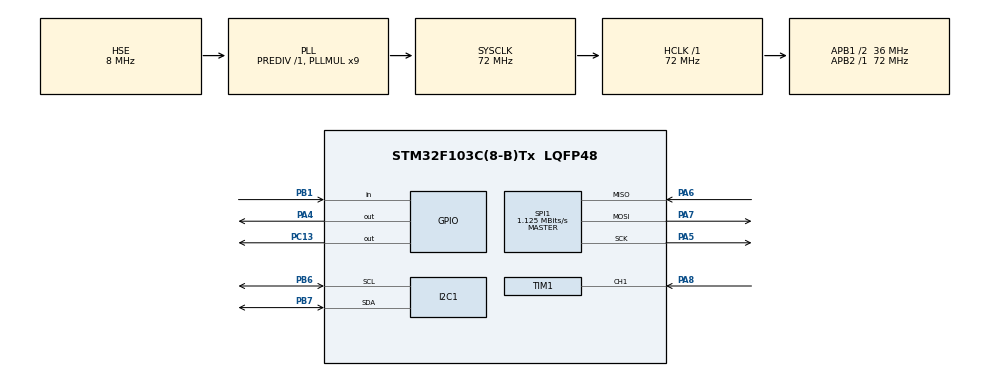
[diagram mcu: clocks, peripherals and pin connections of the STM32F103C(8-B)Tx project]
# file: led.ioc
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Mcu.Family=STM32F1
Mcu.Name=STM32F103C(8-B)Tx
Mcu.Package=LQFP48
NVIC.PriorityGroup=NVIC_PRIORITYGROUP_4
NVIC.TIM1_CC_IRQn=true\:0\:0\:false\:false\:true\:true\:true\:true
NVIC.TIM1_UP_IRQn=true\:0\:0\:false\:false\:true\:true\:true\:true
PA13.Mode=Serial_Wire
PA13.Signal=SYS_JTMS-SWDIO
PA14.Mode=Serial_Wire
PA14.Signal=SYS_JTCK-SWCLK
PA4.GPIO_Speed=GPIO_SPEED_FREQ_HIGH
PA4.PinState=GPIO_PIN_SET
PA4.Signal=GPIO_Output
PA5.Mode=Full_Duplex_Master
PA5.Signal=SPI1_SCK
PA6.Mode=Full_Duplex_Master
PA6.Signal=SPI1_MISO
PA7.Mode=Full_Duplex_Master
PA7.Signal=SPI1_MOSI
PA8.Signal=S_TIM1_CH1
PB1.GPIO_PuPd=GPIO_PULLUP
PB1.Signal=GPIO_Input
PB6.Mode=I2C
PB6.Signal=I2C1_SCL
PB7.Mode=I2C
PB7.Signal=I2C1_SDA
PC13-TAMPER-RTC.PinState=GPIO_PIN_SET
PC13-TAMPER-RTC.Signal=GPIO_Output
PC14-OSC32_IN.Mode=LSE-External-Oscillator
PC14-OSC32_IN.Signal=RCC_OSC32_IN
PC15-OSC32_OUT.Mode=LSE-External-Oscillator
PC15-OSC32_OUT.Signal=RCC_OSC32_OUT
PD0-OSC_IN.Mode=HSE-External-Oscillator
PD0-OSC_IN.Signal=RCC_OSC_IN
PD1-OSC_OUT.Mode=HSE-External-Oscillator
PD1-OSC_OUT.Signal=RCC_OSC_OUT
ProjectManager.HeapSize=0x200
ProjectManager.StackSize=0x400
ProjectManager.TargetToolchain=CMake
RCC.AHBFreq_Value=72000000
RCC.APB1CLKDivider=RCC_HCLK_DIV2
RCC.APB1Freq_Value=36000000
RCC.APB1TimFreq_Value=72000000
RCC.APB2Freq_Value=72000000
RCC.APB2TimFreq_Value=72000000
RCC.HCLKFreq_Value=72000000
RCC.PLLMUL=RCC_PLL_MUL9
RCC.PLLSourceVirtual=RCC_PLLSOURCE_HSE
RCC.SYSCLKFreq_VALUE=72000000
RCC.SYSCLKSource=RCC_SYSCLKSOURCE_PLLCLK
RCC.USBFreq_Value=72000000
SH.S_TIM1_CH1.0=TIM1_CH1,Input_Capture1_from_TI1
SPI1.BaudRatePrescaler=SPI_BAUDRATEPRESCALER_64
SPI1.CalculateBaudRate=1.125 MBits/s
SPI1.Direction=SPI_DIRECTION_2LINES
SPI1.Mode=SPI_MODE_MASTER
SPI1.VirtualType=VM_MASTER
TIM1.AutoReloadPreload=TIM_AUTORELOAD_PRELOAD_ENABLE
TIM1.Channel-Input_Capture1_from_TI1=TIM_CHANNEL_1
TIM1.Channel-Input_Capture2_from_TI1_63=TIM_CHANNEL_2
TIM1.ICPolarity_CH1=TIM_INPUTCHANNELPOLARITY_FALLING
TIM1.ICPolarity_CH2=TIM_INPUTCHANNELPOLARITY_RISING
TIM1.Period=65535
TIM1.Prescaler=71
VP_TIM1_VS_ClockSourceINT.Mode=Internal
VP_TIM1_VS_indirect_ch1.Mode=Input_Capture2_from_TI1_63
board=custom

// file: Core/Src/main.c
/* USER CODE BEGIN Header */
/**
  ******************************************************************************
  * @file           : main.c
  * @brief          : Main program body
  ******************************************************************************
  * @attention
  *
  * Copyright (c) 2025 STMicroelectronics.
  * All rights reserved.
  *
  * This software is licensed under terms that can be found in the LICENSE file
  * in the root directory of this software component.
  * If no LICENSE file comes with this software, it is provided AS-IS.
  *
  ******************************************************************************
  */
/* USER CODE END Header */
#include "main.h"
#include "i2c.h"
#include "spi.h"
#include "tim.h"
#include "gpio.h"

/* USER CODE BEGIN Includes */
#include "math.h"
#include "driver_keyboard.h"
#include "driver_W25Q64.h"
#include "driver_oled_hardware.h"
/* USER CODE END Includes */

void SystemClock_Config(void);

/* USER CODE BEGIN 0 */
// uint8_t led_status = 0;
// uint8_t addr[3] = {0x00, 0x00, 0x00};
// uint8_t write_buffer[] = {0x01, 0x02, 0x03, 0x04};
// uint8_t read_buffer[4] = {0xff, 0xff, 0xff, 0xff};
// uint8_t mid;
// uint16_t did;
/* USER CODE END 0 */

int main(void)
{

  /* MCU Configuration--------------------------------------------------------*/

  /* Reset of all peripherals, Initializes the Flash interface and the Systick. */
  HAL_Init();

  /* Configure the system clock */
  SystemClock_Config();

  /* Initialize all configured peripherals */
  MX_GPIO_Init();
  MX_SPI1_Init();
  MX_I2C1_Init();
  MX_TIM1_Init();
  /* USER CODE BEGIN 2 */
  // OLED_Init();

  // OLED_ShowString(1, 1, "MID:   DID:");
  // OLED_ShowString(2, 1, "W:");
  // OLED_ShowString(3, 1, "R:");

  // ReadID(&mid, &did);
  // OLED_ShowHexNum(1, 5, mid, 2);
  // OLED_ShowHexNum(1, 12, did, 4);

  // SectorErase(addr);
  // ReadData(addr, read_buffer, 4);
  // OLED_ShowHexNum(3, 3, read_buffer[0], 2);
  // OLED_ShowHexNum(3, 6, read_buffer[1], 2);
  // OLED_ShowHexNum(3, 9, read_buffer[2], 2);
  // OLED_ShowHexNum(3, 12, read_buffer[3], 2);

  // PageProgram(addr, write_buffer, 4);

  // ReadData(addr, read_buffer, 4);

  // OLED_ShowHexNum(2, 3, write_buffer[0], 2);
  // OLED_ShowHexNum(2, 6, write_buffer[1], 2);
  // OLED_ShowHexNum(2, 9, write_buffer[2], 2);
  // OLED_ShowHexNum(2, 13, write_buffer[3], 2);

  // OLED_ShowHexNum(3, 3, read_buffer[0], 2);
  // OLED_ShowHexNum(3, 6, read_buffer[1], 2);
  // OLED_ShowHexNum(3, 9, read_buffer[2], 2);
  // OLED_ShowHexNum(3, 12, read_buffer[3], 2);
  // ReadData(addr, &led_status, 1);
  // if (led_status == 0)
  // {
  //   HAL_GPIO_WritePin(GPIOC, GPIO_PIN_13, GPIO_PIN_SET);
  // }
  // else
  // {
  //   HAL_GPIO_WritePin(GPIOC, GPIO_PIN_13, GPIO_PIN_RESET);
  // }
  /* USER CODE END 2 */

  /* Infinite loop */
  /* USER CODE BEGIN WHILE */
  // HAL_TIM_PWM_Start(&htim1, TIM_CHANNEL_1);
  HAL_TIM_IC_Start_IT(&htim1, TIM_CHANNEL_1); // 启动通道 1 的输入捕获
  HAL_TIM_IC_Start_IT(&htim1, TIM_CHANNEL_2); // 启动通道 2 的输入捕获并启用中断
  while (1)
  {
    /* USER CODE END WHILE */

    /* USER CODE BEGIN 3 */
    // float t = HAL_GetTick() / 1000.0f;
    // float duty = 0.5 * sin(2 * 3.14 * t) + 0.5;
    // uint16_t ccr = duty * 1000;
    // __HAL_TIM_SET_COMPARE(&htim1, TIM_CHANNEL_1, ccr);

    // if(Keyboard_GetNum() == 1){
    //   SectorErase(addr);
    //   PageProgram(addr, write_buffer, 4);
    //   write_buffer[0]++;
    //   write_buffer[1]++;
    //   write_buffer[2]++;
    //   write_buffer[3]++;

    //   OLED_ShowHexNum(2, 1, write_buffer[0], 2);
    //   OLED_ShowHexNum(2, 3, write_buffer[1], 2);
    //   OLED_ShowHexNum(2, 5, write_buffer[2], 2);
    //   OLED_ShowHexNum(2, 7, write_buffer[3], 2);

    //   ReadData(addr, read_buffer, 4);
    //   OLED_ShowHexNum(3, 1, read_buffer[0], 2);
    //   OLED_ShowHexNum(3, 3, read_buffer[1], 2);
    //   OLED_ShowHexNum(3, 5, read_buffer[2], 2);
    //   OLED_ShowHexNum(3, 7, read_buffer[3], 2);
    // }
    // if(Keyboard_GetNum() == 1){
    //   HAL_GPIO_TogglePin(GPIOC, GPIO_PIN_13);
    //   if (HAL_GPIO_ReadPin(GPIOC, GPIO_PIN_13) == GPIO_PIN_SET)
    //   {
    //     led_status = 0;
    //   }else{
    //     led_status = 1;
    //   }
    //   SectorErase(addr);
    //   PageProgram(addr, &led_status, 1);
    // }
  }
  /* USER CODE END 3 */
}

void SystemClock_Config(void)
{
  RCC_OscInitTypeDef RCC_OscInitStruct = {0};
  RCC_ClkInitTypeDef RCC_ClkInitStruct = {0};

  /** Initializes the RCC Oscillators according to the specified parameters
  * in the RCC_OscInitTypeDef structure.
  */
  RCC_OscInitStruct.OscillatorType = RCC_OSCILLATORTYPE_HSE;
  RCC_OscInitStruct.HSEState = RCC_HSE_ON;
  RCC_OscInitStruct.HSEPredivValue = RCC_HSE_PREDIV_DIV1;
  RCC_OscInitStruct.HSIState = RCC_HSI_ON;
  RCC_OscInitStruct.PLL.PLLState = RCC_PLL_ON;
  RCC_OscInitStruct.PLL.PLLSource = RCC_PLLSOURCE_HSE;
  RCC_OscInitStruct.PLL.PLLMUL = RCC_PLL_MUL9;
  if (HAL_RCC_OscConfig(&RCC_OscInitStruct) != HAL_OK)
  {
    Error_Handler();
  }

  /** Initializes the CPU, AHB and APB buses clocks
  */
  RCC_ClkInitStruct.ClockType = RCC_CLOCKTYPE_HCLK|RCC_CLOCKTYPE_SYSCLK
                              |RCC_CLOCKTYPE_PCLK1|RCC_CLOCKTYPE_PCLK2;
  RCC_ClkInitStruct.SYSCLKSource = RCC_SYSCLKSOURCE_PLLCLK;
  RCC_ClkInitStruct.AHBCLKDivider = RCC_SYSCLK_DIV1;
  RCC_ClkInitStruct.APB1CLKDivider = RCC_HCLK_DIV2;
  RCC_ClkInitStruct.APB2CLKDivider = RCC_HCLK_DIV1;

  if (HAL_RCC_ClockConfig(&RCC_ClkInitStruct, FLASH_LATENCY_2) != HAL_OK)
  {
    Error_Handler();
  }
}

void Error_Handler(void)
{
  __disable_irq();
  while (1)
  {
  }
}
